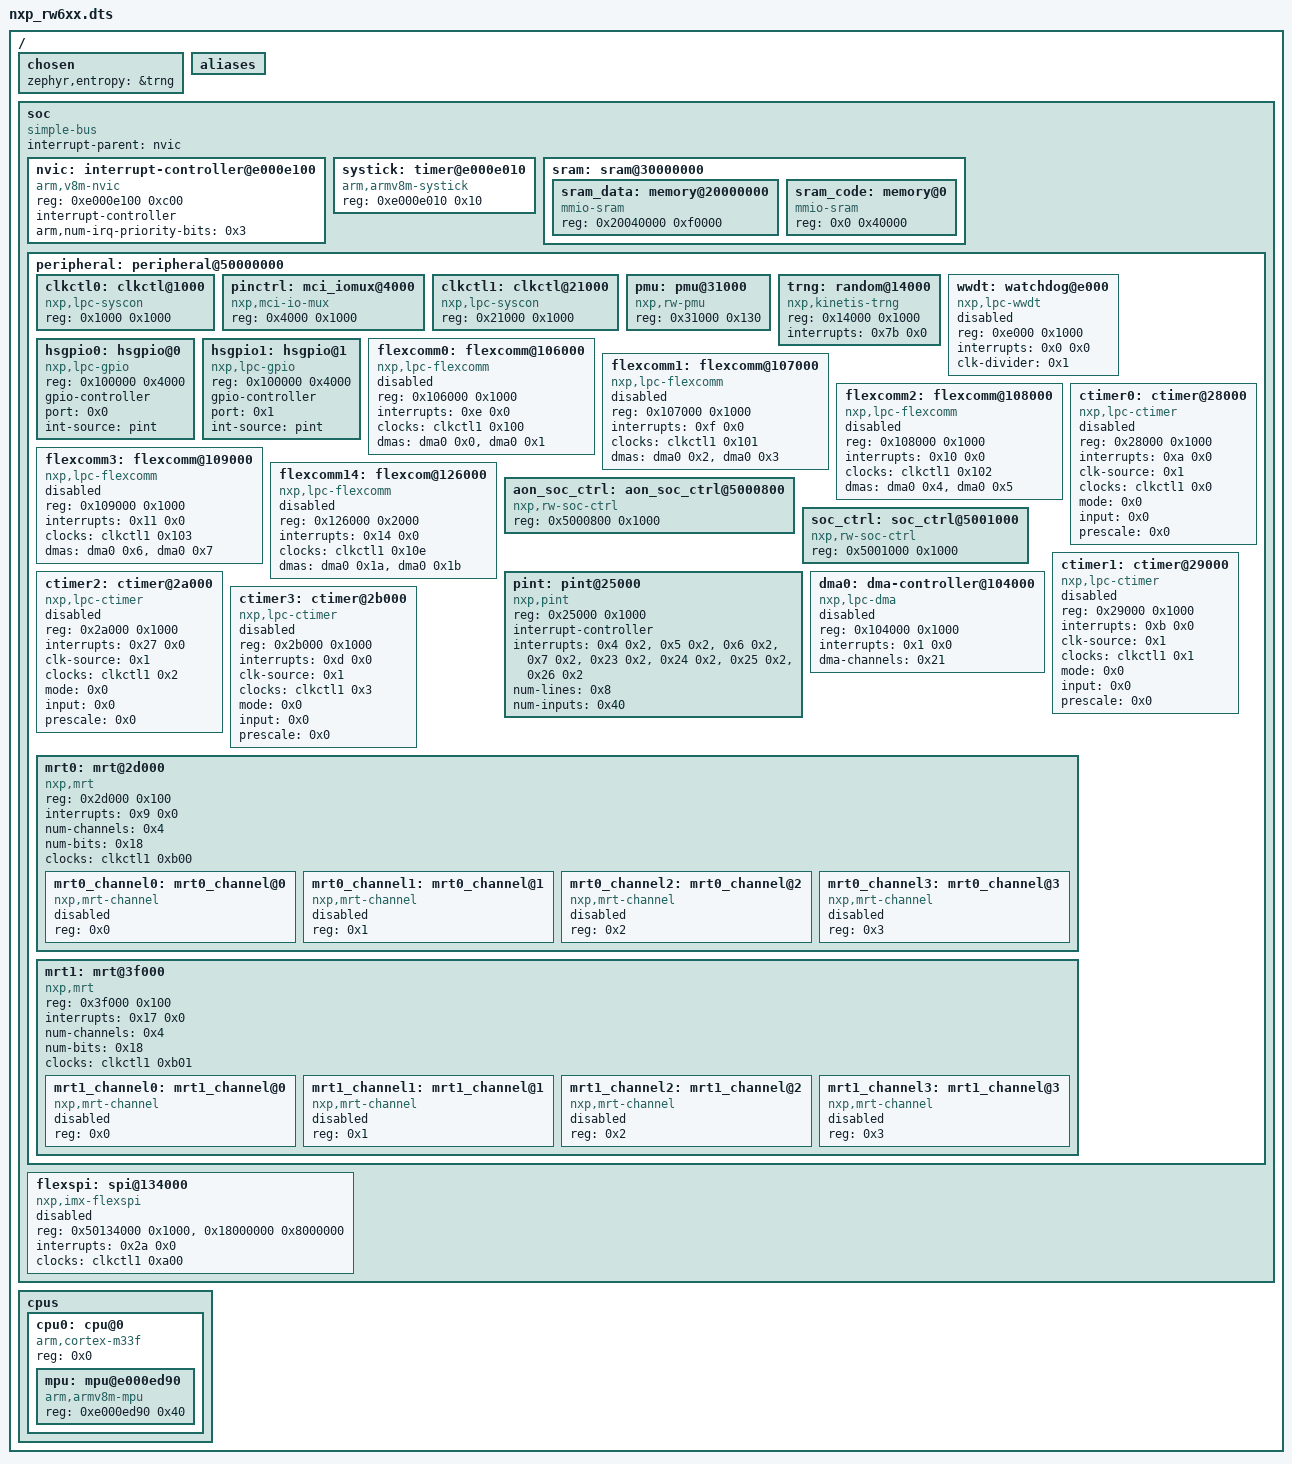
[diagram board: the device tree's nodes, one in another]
/dts-v1/;

/ {
	#address-cells = < 0x1 >;
	#size-cells = < 0x1 >;
	chosen {
		zephyr,entropy = &trng;
	};
	aliases {
	};
	soc {
		#address-cells = < 0x1 >;
		#size-cells = < 0x1 >;
		compatible = "simple-bus";
		interrupt-parent = < &nvic >;
		ranges;
		nvic: interrupt-controller@e000e100 {
			#address-cells = < 0x1 >;
			compatible = "arm,v8m-nvic";
			reg = < 0xe000e100 0xc00 >;
			interrupt-controller;
			#interrupt-cells = < 0x2 >;
			arm,num-irq-priority-bits = < 0x3 >;
			phandle = < 0x1 >;
		};
		systick: timer@e000e010 {
			compatible = "arm,armv8m-systick";
			reg = < 0xe000e010 0x10 >;
		};
		sram: sram@30000000 {
			ranges = < 0x20000000 0x30000000 0x130000 0x0 0x10000000 0x130000 >;
			#address-cells = < 0x1 >;
			#size-cells = < 0x1 >;
			sram_data: memory@20000000 {
				compatible = "mmio-sram";
				reg = < 0x20040000 0xf0000 >;
			};
			sram_code: memory@0 {
				compatible = "mmio-sram";
				reg = < 0x0 0x40000 >;
			};
		};
		peripheral: peripheral@50000000 {
			ranges = < 0x0 0x50000000 0x10000000 >;
			#address-cells = < 0x1 >;
			#size-cells = < 0x1 >;
			clkctl0: clkctl@1000 {
				compatible = "nxp,lpc-syscon";
				reg = < 0x1000 0x1000 >;
				#clock-cells = < 0x1 >;
			};
			pinctrl: mci_iomux@4000 {
				compatible = "nxp,mci-io-mux";
				reg = < 0x4000 0x1000 >;
				status = "okay";
			};
			clkctl1: clkctl@21000 {
				compatible = "nxp,lpc-syscon";
				reg = < 0x21000 0x1000 >;
				#clock-cells = < 0x1 >;
				phandle = < 0x2 >;
			};
			pmu: pmu@31000 {
				reg = < 0x31000 0x130 >;
				compatible = "nxp,rw-pmu";
			};
			trng: random@14000 {
				compatible = "nxp,kinetis-trng";
				reg = < 0x14000 0x1000 >;
				status = "okay";
				interrupts = < 0x7b 0x0 >;
			};
			wwdt: watchdog@e000 {
				compatible = "nxp,lpc-wwdt";
				reg = < 0xe000 0x1000 >;
				interrupts = < 0x0 0x0 >;
				status = "disabled";
				clk-divider = < 0x1 >;
			};
			hsgpio0: hsgpio@0 {
				compatible = "nxp,lpc-gpio";
				reg = < 0x100000 0x4000 >;
				gpio-controller;
				#gpio-cells = < 0x2 >;
				port = < 0x0 >;
				int-source = "pint";
			};
			hsgpio1: hsgpio@1 {
				compatible = "nxp,lpc-gpio";
				reg = < 0x100000 0x4000 >;
				gpio-controller;
				#gpio-cells = < 0x2 >;
				port = < 0x1 >;
				int-source = "pint";
			};
			flexcomm0: flexcomm@106000 {
				compatible = "nxp,lpc-flexcomm";
				reg = < 0x106000 0x1000 >;
				interrupts = < 0xe 0x0 >;
				clocks = < &clkctl1 0x100 >;
				dmas = < &dma0 0x0 >, < &dma0 0x1 >;
				dma-names = "rx", "tx";
				status = "disabled";
			};
			flexcomm1: flexcomm@107000 {
				compatible = "nxp,lpc-flexcomm";
				reg = < 0x107000 0x1000 >;
				interrupts = < 0xf 0x0 >;
				clocks = < &clkctl1 0x101 >;
				dmas = < &dma0 0x2 >, < &dma0 0x3 >;
				dma-names = "rx", "tx";
				status = "disabled";
			};
			flexcomm2: flexcomm@108000 {
				compatible = "nxp,lpc-flexcomm";
				reg = < 0x108000 0x1000 >;
				interrupts = < 0x10 0x0 >;
				clocks = < &clkctl1 0x102 >;
				dmas = < &dma0 0x4 >, < &dma0 0x5 >;
				dma-names = "rx", "tx";
				status = "disabled";
			};
			flexcomm3: flexcomm@109000 {
				compatible = "nxp,lpc-flexcomm";
				reg = < 0x109000 0x1000 >;
				interrupts = < 0x11 0x0 >;
				clocks = < &clkctl1 0x103 >;
				dmas = < &dma0 0x6 >, < &dma0 0x7 >;
				dma-names = "rx", "tx";
				status = "disabled";
			};
			flexcomm14: flexcom@126000 {
				compatible = "nxp,lpc-flexcomm";
				reg = < 0x126000 0x2000 >;
				interrupts = < 0x14 0x0 >;
				clocks = < &clkctl1 0x10e >;
				dmas = < &dma0 0x1a >, < &dma0 0x1b >;
				dma-names = "rx", "tx";
				status = "disabled";
			};
			aon_soc_ctrl: aon_soc_ctrl@5000800 {
				compatible = "nxp,rw-soc-ctrl";
				reg = < 0x5000800 0x1000 >;
				status = "okay";
			};
			soc_ctrl: soc_ctrl@5001000 {
				compatible = "nxp,rw-soc-ctrl";
				reg = < 0x5001000 0x1000 >;
				status = "okay";
			};
			pint: pint@25000 {
				compatible = "nxp,pint";
				reg = < 0x25000 0x1000 >;
				interrupt-controller;
				#interrupt-cells = < 0x1 >;
				#address-cells = < 0x0 >;
				interrupts = < 0x4 0x2 >, < 0x5 0x2 >, < 0x6 0x2 >, < 0x7 0x2 >, < 0x23 0x2 >, < 0x24 0x2 >, < 0x25 0x2 >, < 0x26 0x2 >;
				num-lines = < 0x8 >;
				num-inputs = < 0x40 >;
			};
			dma0: dma-controller@104000 {
				compatible = "nxp,lpc-dma";
				reg = < 0x104000 0x1000 >;
				interrupts = < 0x1 0x0 >;
				status = "disabled";
				#dma-cells = < 0x1 >;
				dma-channels = < 0x21 >;
				phandle = < 0x3 >;
			};
			ctimer0: ctimer@28000 {
				compatible = "nxp,lpc-ctimer";
				reg = < 0x28000 0x1000 >;
				interrupts = < 0xa 0x0 >;
				status = "disabled";
				clk-source = < 0x1 >;
				clocks = < &clkctl1 0x0 >;
				mode = < 0x0 >;
				input = < 0x0 >;
				prescale = < 0x0 >;
			};
			ctimer1: ctimer@29000 {
				compatible = "nxp,lpc-ctimer";
				reg = < 0x29000 0x1000 >;
				interrupts = < 0xb 0x0 >;
				status = "disabled";
				clk-source = < 0x1 >;
				clocks = < &clkctl1 0x1 >;
				mode = < 0x0 >;
				input = < 0x0 >;
				prescale = < 0x0 >;
			};
			ctimer2: ctimer@2a000 {
				compatible = "nxp,lpc-ctimer";
				reg = < 0x2a000 0x1000 >;
				interrupts = < 0x27 0x0 >;
				status = "disabled";
				clk-source = < 0x1 >;
				clocks = < &clkctl1 0x2 >;
				mode = < 0x0 >;
				input = < 0x0 >;
				prescale = < 0x0 >;
			};
			ctimer3: ctimer@2b000 {
				compatible = "nxp,lpc-ctimer";
				reg = < 0x2b000 0x1000 >;
				interrupts = < 0xd 0x0 >;
				status = "disabled";
				clk-source = < 0x1 >;
				clocks = < &clkctl1 0x3 >;
				mode = < 0x0 >;
				input = < 0x0 >;
				prescale = < 0x0 >;
			};
			mrt0: mrt@2d000 {
				compatible = "nxp,mrt";
				reg = < 0x2d000 0x100 >;
				interrupts = < 0x9 0x0 >;
				num-channels = < 0x4 >;
				num-bits = < 0x18 >;
				clocks = < &clkctl1 0xb00 >;
				#address-cells = < 0x1 >;
				#size-cells = < 0x0 >;
				mrt0_channel0: mrt0_channel@0 {
					compatible = "nxp,mrt-channel";
					reg = < 0x0 >;
					status = "disabled";
				};
				mrt0_channel1: mrt0_channel@1 {
					compatible = "nxp,mrt-channel";
					reg = < 0x1 >;
					status = "disabled";
				};
				mrt0_channel2: mrt0_channel@2 {
					compatible = "nxp,mrt-channel";
					reg = < 0x2 >;
					status = "disabled";
				};
				mrt0_channel3: mrt0_channel@3 {
					compatible = "nxp,mrt-channel";
					reg = < 0x3 >;
					status = "disabled";
				};
			};
			mrt1: mrt@3f000 {
				compatible = "nxp,mrt";
				reg = < 0x3f000 0x100 >;
				interrupts = < 0x17 0x0 >;
				num-channels = < 0x4 >;
				num-bits = < 0x18 >;
				clocks = < &clkctl1 0xb01 >;
				#address-cells = < 0x1 >;
				#size-cells = < 0x0 >;
				mrt1_channel0: mrt1_channel@0 {
					compatible = "nxp,mrt-channel";
					reg = < 0x0 >;
					status = "disabled";
				};
				mrt1_channel1: mrt1_channel@1 {
					compatible = "nxp,mrt-channel";
					reg = < 0x1 >;
					status = "disabled";
				};
				mrt1_channel2: mrt1_channel@2 {
					compatible = "nxp,mrt-channel";
					reg = < 0x2 >;
					status = "disabled";
				};
				mrt1_channel3: mrt1_channel@3 {
					compatible = "nxp,mrt-channel";
					reg = < 0x3 >;
					status = "disabled";
				};
			};
		};
		flexspi: spi@134000 {
			reg = < 0x50134000 0x1000 >, < 0x18000000 0x8000000 >;
			compatible = "nxp,imx-flexspi";
			status = "disabled";
			interrupts = < 0x2a 0x0 >;
			#address-cells = < 0x1 >;
			#size-cells = < 0x0 >;
			clocks = < &clkctl1 0xa00 >;
		};
	};
	cpus {
		#address-cells = < 0x1 >;
		#size-cells = < 0x0 >;
		cpu0: cpu@0 {
			compatible = "arm,cortex-m33f";
			reg = < 0x0 >;
			#address-cells = < 0x1 >;
			#size-cells = < 0x1 >;
			mpu: mpu@e000ed90 {
				compatible = "arm,armv8m-mpu";
				reg = < 0xe000ed90 0x40 >;
			};
		};
	};
};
